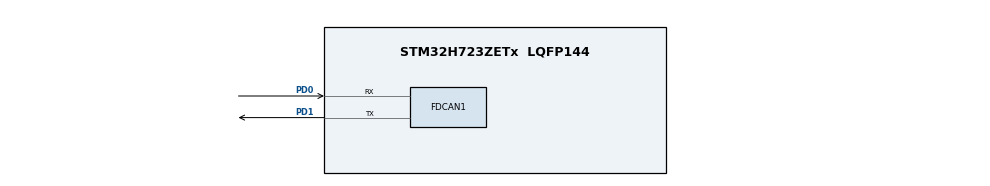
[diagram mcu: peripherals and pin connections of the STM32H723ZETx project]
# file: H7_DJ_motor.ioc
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CORTEX_M7.IsCacheable_Spec=MPU_ACCESS_CACHEABLE
CORTEX_M7.IsShareable_Spec=MPU_ACCESS_NOT_SHAREABLE
CORTEX_M7.default_mode_Activation=1
FDCAN1.CalculateBaudRateNominal=1000000
FDCAN1.CalculateTimeBitNominal=1000
FDCAN1.CalculateTimeQuantumNominal=25.0
FDCAN1.ExtFiltersNbr=0
FDCAN1.NominalPrescaler=1
FDCAN1.NominalSyncJumpWidth=8
FDCAN1.NominalTimeSeg1=31
FDCAN1.NominalTimeSeg2=8
FDCAN1.RxFifo0ElmtsNbr=3
FDCAN1.StdFiltersNbr=1
FDCAN1.TxFifoQueueElmtsNbr=3
Mcu.Family=STM32H7
Mcu.Name=STM32H723ZETx
Mcu.Package=LQFP144
NVIC.FDCAN1_IT0_IRQn=true\:0\:0\:false\:false\:true\:true\:true\:true
NVIC.FDCAN1_IT1_IRQn=true\:0\:0\:false\:false\:true\:true\:true\:true
NVIC.PriorityGroup=NVIC_PRIORITYGROUP_4
NVIC.TIM2_IRQn=true\:0\:0\:false\:false\:true\:true\:true\:true
NVIC.TIM6_DAC_IRQn=true\:15\:0\:false\:false\:true\:false\:true\:true
NVIC.TimeBase=TIM6_DAC_IRQn
NVIC.TimeBaseIP=TIM6
PD0.Mode=FDCAN_Activate
PD0.Signal=FDCAN1_RX
PD1.Mode=FDCAN_Activate
PD1.Signal=FDCAN1_TX
PH0-OSC_IN.Mode=HSE-External-Oscillator
PH0-OSC_IN.Signal=RCC_OSC_IN
PH1-OSC_OUT.Mode=HSE-External-Oscillator
PH1-OSC_OUT.Signal=RCC_OSC_OUT
ProjectManager.HeapSize=0x200
ProjectManager.StackSize=0x400
ProjectManager.TargetToolchain=MDK-ARM V5.32
RCC.ADCFreq_Value=100000000
RCC.APB1Freq_Value=137500000
RCC.APB2Freq_Value=137500000
RCC.APB3Freq_Value=137500000
RCC.APB4Freq_Value=137500000
RCC.CortexFreq_Value=550000000
RCC.D1PPRE=RCC_APB3_DIV2
RCC.D2PPRE1=RCC_APB1_DIV2
RCC.D2PPRE2=RCC_APB2_DIV2
RCC.D3PPRE=RCC_APB4_DIV2
RCC.DIVM1=2
RCC.DIVM2=2
RCC.DIVN1=44
RCC.DIVN2=16
RCC.DIVP1=1
RCC.DIVQ1=4
RCC.DIVQ2=5
RCC.FDCANCLockSelection=RCC_FDCANCLKSOURCE_PLL2
RCC.HCLKFreq_Value=275000000
RCC.HPRE=RCC_HCLK_DIV2
RCC.PLL2FRACN=0
RCC.PLL3FRACN=0
RCC.PLLFRACN=0
RCC.PLLSourceVirtual=RCC_PLLSOURCE_HSE
RCC.SYSCLKFreq_VALUE=550000000
RCC.SYSCLKSource=RCC_SYSCLKSOURCE_PLLCLK
RCC.USBFreq_Value=137500000
TIM2.Period=999
TIM2.Prescaler=274
VP_MEMORYMAP_VS_MEMORYMAP.Mode=CurAppReg
VP_SYS_VS_tim6.Mode=TIM6
VP_TIM2_VS_ClockSourceINT.Mode=Internal
board=custom

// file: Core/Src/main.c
/* USER CODE BEGIN Header */
/**
  ******************************************************************************
  * @file           : main.c
  * @brief          : Main program body
  ******************************************************************************
  * @attention
  *
  * Copyright (c) 2026 STMicroelectronics.
  * All rights reserved.
  *
  * This software is licensed under terms that can be found in the LICENSE file
  * in the root directory of this software component.
  * If no LICENSE file comes with this software, it is provided AS-IS.
  *
  ******************************************************************************
  */
/* USER CODE END Header */
#include "main.h"
#include "fdcan.h"
#include "tim.h"
#include "gpio.h"

/* USER CODE BEGIN Includes */
#include "dj_motor.h"
/* USER CODE END Includes */

void SystemClock_Config(void);
static void MPU_Config(void);

int main(void)
{

  /* MPU Configuration--------------------------------------------------------*/
  MPU_Config();

  /* MCU Configuration--------------------------------------------------------*/

  /* Reset of all peripherals, Initializes the Flash interface and the Systick. */
  HAL_Init();

  /* Configure the system clock */
  SystemClock_Config();

  /* Initialize all configured peripherals */
  MX_GPIO_Init();
  MX_FDCAN1_Init();
  MX_TIM2_Init();
  /* USER CODE BEGIN 2 */
  //只接收大疆反馈帧 0x201~0x208 进 FIFO0
  FDCAN_FilterTypeDef sFilterConfig = {0};
  sFilterConfig.IdType       = FDCAN_STANDARD_ID;
  sFilterConfig.FilterIndex  = 0;
  sFilterConfig.FilterType   = FDCAN_FILTER_RANGE;
  sFilterConfig.FilterConfig = FDCAN_FILTER_TO_RXFIFO0;
  sFilterConfig.FilterID1    = 0x201;
  sFilterConfig.FilterID2    = 0x208;
  if (HAL_FDCAN_ConfigFilter(&hfdcan1, &sFilterConfig) != HAL_OK)
  {
    Error_Handler();
  }

  if (HAL_FDCAN_Start(&hfdcan1) != HAL_OK)
  {
    Error_Handler();
  }

  /* 打开 RX FIFO0 新消息中断,否则收不到电机反馈 */
  if (HAL_FDCAN_ActivateNotification(&hfdcan1, FDCAN_IT_RX_FIFO0_NEW_MESSAGE, 0) != HAL_OK)
  {
    Error_Handler();
  }

  DJmotor_Init();

  /* 启动 TIM2 1kHz 中断(解包与状态机周期) */
  HAL_TIM_Base_Start_IT(&htim2);
  /* USER CODE END 2 */

  /* Infinite loop */
  while (1)
  {

  }
}

void SystemClock_Config(void)
{
  RCC_OscInitTypeDef RCC_OscInitStruct = {0};
  RCC_ClkInitTypeDef RCC_ClkInitStruct = {0};

  /** Supply configuration update enable
  */
  HAL_PWREx_ConfigSupply(PWR_LDO_SUPPLY);

  /** Configure the main internal regulator output voltage
  */
  __HAL_PWR_VOLTAGESCALING_CONFIG(PWR_REGULATOR_VOLTAGE_SCALE0);

  while(!__HAL_PWR_GET_FLAG(PWR_FLAG_VOSRDY)) {}

  /** Initializes the RCC Oscillators according to the specified parameters
  * in the RCC_OscInitTypeDef structure.
  */
  RCC_OscInitStruct.OscillatorType = RCC_OSCILLATORTYPE_HSE;
  RCC_OscInitStruct.HSEState = RCC_HSE_ON;
  RCC_OscInitStruct.PLL.PLLState = RCC_PLL_ON;
  RCC_OscInitStruct.PLL.PLLSource = RCC_PLLSOURCE_HSE;
  RCC_OscInitStruct.PLL.PLLM = 2;
  RCC_OscInitStruct.PLL.PLLN = 44;
  RCC_OscInitStruct.PLL.PLLP = 1;
  RCC_OscInitStruct.PLL.PLLQ = 4;
  RCC_OscInitStruct.PLL.PLLR = 2;
  RCC_OscInitStruct.PLL.PLLRGE = RCC_PLL1VCIRANGE_3;
  RCC_OscInitStruct.PLL.PLLVCOSEL = RCC_PLL1VCOWIDE;
  RCC_OscInitStruct.PLL.PLLFRACN = 0;
  if (HAL_RCC_OscConfig(&RCC_OscInitStruct) != HAL_OK)
  {
    Error_Handler();
  }

  /** Initializes the CPU, AHB and APB buses clocks
  */
  RCC_ClkInitStruct.ClockType = RCC_CLOCKTYPE_HCLK|RCC_CLOCKTYPE_SYSCLK
                              |RCC_CLOCKTYPE_PCLK1|RCC_CLOCKTYPE_PCLK2
                              |RCC_CLOCKTYPE_D3PCLK1|RCC_CLOCKTYPE_D1PCLK1;
  RCC_ClkInitStruct.SYSCLKSource = RCC_SYSCLKSOURCE_PLLCLK;
  RCC_ClkInitStruct.SYSCLKDivider = RCC_SYSCLK_DIV1;
  RCC_ClkInitStruct.AHBCLKDivider = RCC_HCLK_DIV2;
  RCC_ClkInitStruct.APB3CLKDivider = RCC_APB3_DIV2;
  RCC_ClkInitStruct.APB1CLKDivider = RCC_APB1_DIV2;
  RCC_ClkInitStruct.APB2CLKDivider = RCC_APB2_DIV2;
  RCC_ClkInitStruct.APB4CLKDivider = RCC_APB4_DIV2;

  if (HAL_RCC_ClockConfig(&RCC_ClkInitStruct, FLASH_LATENCY_3) != HAL_OK)
  {
    Error_Handler();
  }
}

/* USER CODE BEGIN 4 */
void HAL_FDCAN_RxFifo0Callback(FDCAN_HandleTypeDef *hfdcan, uint32_t RxFifo0ITs)
{
  FDCAN_RxHeaderTypeDef rx_header;
  uint8_t rx_data[8];
  if (hfdcan == &hfdcan1)
  {
    if (HAL_FDCAN_GetRxMessage(hfdcan, FDCAN_RX_FIFO0, &rx_header, rx_data) == HAL_OK)
    {
      DJmotor_RxPush(rx_header, rx_data);
    }
  }
}
/* USER CODE END 4 */

 /* MPU Configuration */

void MPU_Config(void)
{
  MPU_Region_InitTypeDef MPU_InitStruct = {0};

  /* Disables the MPU */
  HAL_MPU_Disable();

  /** Initializes and configures the Region and the memory to be protected
  */
  MPU_InitStruct.Enable = MPU_REGION_ENABLE;
  MPU_InitStruct.Number = MPU_REGION_NUMBER0;
  MPU_InitStruct.BaseAddress = 0x0;
  MPU_InitStruct.Size = MPU_REGION_SIZE_4GB;
  MPU_InitStruct.SubRegionDisable = 0x87;
  MPU_InitStruct.TypeExtField = MPU_TEX_LEVEL0;
  MPU_InitStruct.AccessPermission = MPU_REGION_NO_ACCESS;
  MPU_InitStruct.DisableExec = MPU_INSTRUCTION_ACCESS_DISABLE;
  MPU_InitStruct.IsShareable = MPU_ACCESS_NOT_SHAREABLE;
  MPU_InitStruct.IsCacheable = MPU_ACCESS_CACHEABLE;
  MPU_InitStruct.IsBufferable = MPU_ACCESS_NOT_BUFFERABLE;

  HAL_MPU_ConfigRegion(&MPU_InitStruct);
  /* Enables the MPU */
  HAL_MPU_Enable(MPU_PRIVILEGED_DEFAULT);

}

void HAL_TIM_PeriodElapsedCallback(TIM_HandleTypeDef *htim)
{
  if (htim->Instance == TIM6)
  {
    HAL_IncTick();
  }
  /* USER CODE BEGIN Callback 1 */
  if (htim->Instance == TIM2)
  {
    DJmotor_RxProcess();
    DJmotor_Func();
  }
  /* USER CODE END Callback 1 */
}

void Error_Handler(void)
{
  __disable_irq();
  while (1)
  {
  }
}
